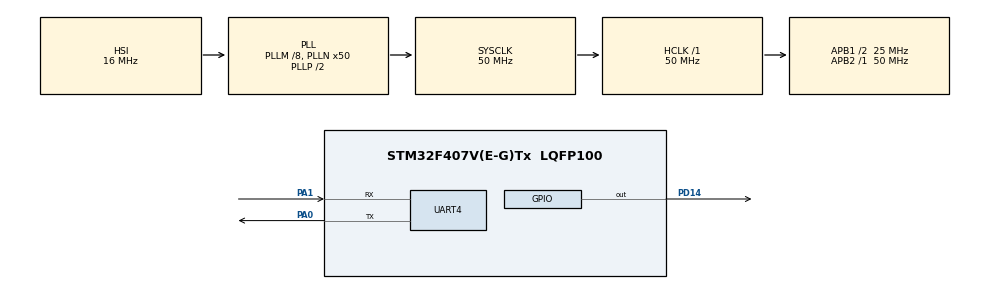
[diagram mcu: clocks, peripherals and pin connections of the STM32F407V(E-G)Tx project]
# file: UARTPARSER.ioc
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Dma.Request0=UART4_RX
Dma.UART4_RX.0.Direction=DMA_PERIPH_TO_MEMORY
Dma.UART4_RX.0.FIFOMode=DMA_FIFOMODE_DISABLE
Dma.UART4_RX.0.Instance=DMA1_Stream2
Dma.UART4_RX.0.MemDataAlignment=DMA_MDATAALIGN_BYTE
Dma.UART4_RX.0.MemInc=DMA_MINC_ENABLE
Dma.UART4_RX.0.Mode=DMA_NORMAL
Dma.UART4_RX.0.PeriphDataAlignment=DMA_PDATAALIGN_BYTE
Dma.UART4_RX.0.PeriphInc=DMA_PINC_DISABLE
Dma.UART4_RX.0.Priority=DMA_PRIORITY_LOW
Mcu.Family=STM32F4
Mcu.Name=STM32F407V(E-G)Tx
Mcu.Package=LQFP100
NVIC.DMA1_Stream2_IRQn=true\:0\:0\:false\:false\:true\:false\:true
NVIC.PriorityGroup=NVIC_PRIORITYGROUP_4
PA0-WKUP.Mode=Asynchronous
PA0-WKUP.Signal=UART4_TX
PA1.Mode=Asynchronous
PA1.Signal=UART4_RX
PD14.Signal=GPIO_Output
ProjectManager.HeapSize=0x200
ProjectManager.StackSize=0x400
ProjectManager.TargetToolchain=STM32CubeIDE
RCC.48MHZClocksFreq_Value=25000000
RCC.AHBFreq_Value=50000000
RCC.APB1CLKDivider=RCC_HCLK_DIV2
RCC.APB1Freq_Value=25000000
RCC.APB1TimFreq_Value=50000000
RCC.APB2Freq_Value=50000000
RCC.APB2TimFreq_Value=50000000
RCC.CortexFreq_Value=50000000
RCC.HCLKFreq_Value=50000000
RCC.HSE_VALUE=25000000
RCC.HSI_VALUE=16000000
RCC.LSE_VALUE=32768
RCC.PLLM=8
RCC.PLLN=50
RCC.SYSCLKFreq_VALUE=50000000
RCC.SYSCLKSource=RCC_SYSCLKSOURCE_PLLCLK
RCC.VCOOutputFreq_Value=100000000
UART4.VirtualMode=Asynchronous
board=custom

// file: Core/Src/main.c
/* USER CODE BEGIN Header */
/**
  ******************************************************************************
  * @file           : main.c
  * @brief          : Main program body
  ******************************************************************************
  * @attention
  *
  * <h2><center>&copy; Copyright (c) 2021 STMicroelectronics.
  * All rights reserved.</center></h2>
  *
  * This software component is licensed by ST under BSD 3-Clause license,
  * the "License"; You may not use this file except in compliance with the
  * License. You may obtain a copy of the License at:
  *                        opensource.org/licenses/BSD-3-Clause
  *
  ******************************************************************************
  */
/* USER CODE END Header */

#include "main.h"
#include "UART_Parser.h"

//UART_HandleTypeDef huart4;
//DMA_HandleTypeDef hdma_uart4_rx;

void SystemClock_Config(void);
static void MX_GPIO_Init(void);
static void MX_DMA_Init(void);
static void MX_UART4_Init(void);

int main(void)
{

  /* MCU Configuration--------------------------------------------------------*/

  /* Reset of all peripherals, Initializes the Flash interface and the Systick. */
  HAL_Init();

  /* Configure the system clock */
  SystemClock_Config();

  /* Initialize all configured peripherals */
  MX_GPIO_Init();
  MX_DMA_Init();
  MX_UART4_Init();
  /* USER CODE BEGIN 2 */
  UARTParserInit();
  /* USER CODE END 2 */

  /* Infinite loop */
  while (1)
  {
	 HAL_GPIO_TogglePin(GPIOD, GPIO_PIN_14);
	  for(int i=0;i<500000;i++){
	  }
	  Commands_Processing();

  }
  /* USER CODE END 3 */
}

void SystemClock_Config(void)
{
  RCC_OscInitTypeDef RCC_OscInitStruct = {0};
  RCC_ClkInitTypeDef RCC_ClkInitStruct = {0};

  /** Configure the main internal regulator output voltage
  */
  __HAL_RCC_PWR_CLK_ENABLE();
  __HAL_PWR_VOLTAGESCALING_CONFIG(PWR_REGULATOR_VOLTAGE_SCALE1);
  /** Initializes the CPU, AHB and APB busses clocks
  */
  RCC_OscInitStruct.OscillatorType = RCC_OSCILLATORTYPE_HSI;
  RCC_OscInitStruct.HSIState = RCC_HSI_ON;
  RCC_OscInitStruct.HSICalibrationValue = RCC_HSICALIBRATION_DEFAULT;
  RCC_OscInitStruct.PLL.PLLState = RCC_PLL_ON;
  RCC_OscInitStruct.PLL.PLLSource = RCC_PLLSOURCE_HSI;
  RCC_OscInitStruct.PLL.PLLM = 8;
  RCC_OscInitStruct.PLL.PLLN = 50;
  RCC_OscInitStruct.PLL.PLLP = RCC_PLLP_DIV2;
  RCC_OscInitStruct.PLL.PLLQ = 4;
  if (HAL_RCC_OscConfig(&RCC_OscInitStruct) != HAL_OK)
  {
    Error_Handler();
  }
  /** Initializes the CPU, AHB and APB busses clocks
  */
  RCC_ClkInitStruct.ClockType = RCC_CLOCKTYPE_HCLK|RCC_CLOCKTYPE_SYSCLK
                              |RCC_CLOCKTYPE_PCLK1|RCC_CLOCKTYPE_PCLK2;
  RCC_ClkInitStruct.SYSCLKSource = RCC_SYSCLKSOURCE_PLLCLK;
  RCC_ClkInitStruct.AHBCLKDivider = RCC_SYSCLK_DIV1;
  RCC_ClkInitStruct.APB1CLKDivider = RCC_HCLK_DIV2;
  RCC_ClkInitStruct.APB2CLKDivider = RCC_HCLK_DIV1;

  if (HAL_RCC_ClockConfig(&RCC_ClkInitStruct, FLASH_LATENCY_1) != HAL_OK)
  {
    Error_Handler();
  }
}

static void MX_UART4_Init(void)
{

  huart4.Instance = UART4;
  huart4.Init.BaudRate = 115200;
  huart4.Init.WordLength = UART_WORDLENGTH_8B;
  huart4.Init.StopBits = UART_STOPBITS_1;
  huart4.Init.Parity = UART_PARITY_NONE;
  huart4.Init.Mode = UART_MODE_TX_RX;
  huart4.Init.HwFlowCtl = UART_HWCONTROL_NONE;
  huart4.Init.OverSampling = UART_OVERSAMPLING_16;
  if (HAL_UART_Init(&huart4) != HAL_OK)
  {
    Error_Handler();
  }

}

static void MX_DMA_Init(void)
{

  /* DMA controller clock enable */
  __HAL_RCC_DMA1_CLK_ENABLE();

  /* DMA interrupt init */
  /* DMA1_Stream2_IRQn interrupt configuration */
  HAL_NVIC_SetPriority(DMA1_Stream2_IRQn, 0, 0);
  HAL_NVIC_EnableIRQ(DMA1_Stream2_IRQn);

}

static void MX_GPIO_Init(void)
{
  GPIO_InitTypeDef GPIO_InitStruct = {0};

  /* GPIO Ports Clock Enable */
  __HAL_RCC_GPIOA_CLK_ENABLE();
  __HAL_RCC_GPIOD_CLK_ENABLE();

  /*Configure GPIO pin Output Level */
  HAL_GPIO_WritePin(GPIOD, GPIO_PIN_14, GPIO_PIN_RESET);

  /*Configure GPIO pin : PD14 */
  GPIO_InitStruct.Pin = GPIO_PIN_14;
  GPIO_InitStruct.Mode = GPIO_MODE_OUTPUT_PP;
  GPIO_InitStruct.Pull = GPIO_NOPULL;
  GPIO_InitStruct.Speed = GPIO_SPEED_FREQ_LOW;
  HAL_GPIO_Init(GPIOD, &GPIO_InitStruct);

}

void Error_Handler(void)
{
}

/************************ (C) COPYRIGHT STMicroelectronics *****END OF FILE****/
